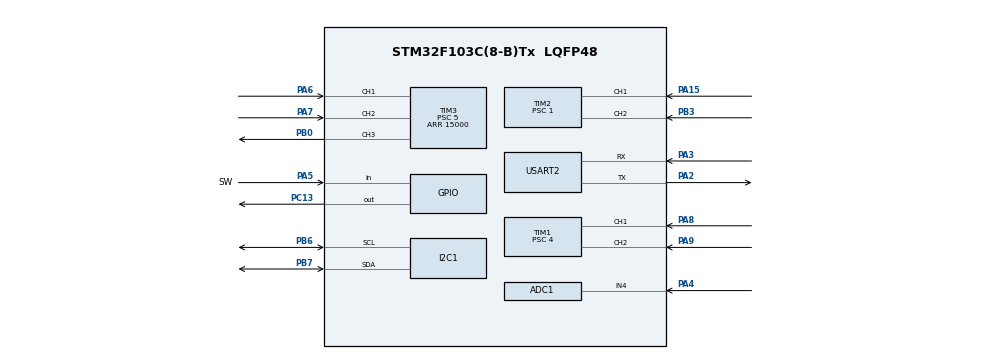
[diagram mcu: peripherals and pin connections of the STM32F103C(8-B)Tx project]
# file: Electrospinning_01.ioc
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ADC1.Channel-5\#ChannelRegularConversion=ADC_CHANNEL_4
ADC1.NbrOfConversionFlag=1
ADC1.Rank-5\#ChannelRegularConversion=1
ADC1.SamplingTime-5\#ChannelRegularConversion=ADC_SAMPLETIME_1CYCLE_5
ADC1.master=1
Mcu.Family=STM32F1
Mcu.Name=STM32F103C(8-B)Tx
Mcu.Package=LQFP48
NVIC.PriorityGroup=NVIC_PRIORITYGROUP_4
NVIC.TIM2_IRQn=true\:0\:0\:false\:false\:true\:true
NVIC.TIM4_IRQn=true\:0\:0\:false\:false\:true\:true
PA13.Mode=Serial_Wire
PA13.Signal=SYS_JTMS-SWDIO
PA14.Mode=Serial_Wire
PA14.Signal=SYS_JTCK-SWCLK
PA15.GPIO_PuPd=GPIO_PULLUP
PA15.Signal=S_TIM2_CH1_ETR
PA2.Mode=Asynchronous
PA2.Signal=USART2_TX
PA3.Mode=Asynchronous
PA3.Signal=USART2_RX
PA4.Signal=ADCx_IN4
PA5.GPIO_Label=SW
PA5.Signal=GPIO_Input
PA6.Signal=S_TIM3_CH1
PA7.Signal=S_TIM3_CH2
PA8.Signal=S_TIM1_CH1
PA9.Signal=S_TIM1_CH2
PB0.Signal=S_TIM3_CH3
PB3.GPIO_PuPd=GPIO_PULLUP
PB3.Signal=S_TIM2_CH2
PB6.Mode=I2C
PB6.Signal=I2C1_SCL
PB7.Mode=I2C
PB7.Signal=I2C1_SDA
PC13-TAMPER-RTC.Signal=GPIO_Output
PC14-OSC32_IN.Mode=LSE-External-Oscillator
PC14-OSC32_IN.Signal=RCC_OSC32_IN
PC15-OSC32_OUT.Mode=LSE-External-Oscillator
PC15-OSC32_OUT.Signal=RCC_OSC32_OUT
PD0-OSC_IN.Mode=HSE-External-Oscillator
PD0-OSC_IN.Signal=RCC_OSC_IN
PD1-OSC_OUT.Mode=HSE-External-Oscillator
PD1-OSC_OUT.Signal=RCC_OSC_OUT
ProjectManager.HeapSize=0x200
ProjectManager.StackSize=0x400
ProjectManager.TargetToolchain=MDK-ARM V5
RCC.APB1Freq_Value=8000000
RCC.APB2Freq_Value=8000000
SH.ADCx_IN4.0=ADC1_IN4,IN4
SH.S_TIM1_CH1.0=TIM1_CH1,Encoder_Interface
SH.S_TIM1_CH2.0=TIM1_CH2,Encoder_Interface
SH.S_TIM2_CH1_ETR.0=TIM2_CH1,Encoder_Interface
SH.S_TIM2_CH2.0=TIM2_CH2,Encoder_Interface
SH.S_TIM3_CH1.0=TIM3_CH1,Encoder_Interface
SH.S_TIM3_CH2.0=TIM3_CH2,Encoder_Interface
SH.S_TIM3_CH3.0=TIM3_CH3,PWM Generation3 CH3
TIM1.Prescaler=4
TIM2.EncoderMode=TIM_ENCODERMODE_TI1
TIM2.IC1Polarity=TIM_ICPOLARITY_FALLING
TIM2.IC2Filter=15
TIM2.IC2Polarity=TIM_ICPOLARITY_FALLING
TIM2.Period=0xffff
TIM2.Prescaler=1
TIM3.Channel-PWM\ Generation3\ CH3=TIM_CHANNEL_3
TIM3.Period=15000
TIM3.Prescaler=5
TIM4.AutoReloadPreload=TIM_AUTORELOAD_PRELOAD_ENABLE
TIM4.Period=100
TIM4.Prescaler=7200
USART2.VirtualMode=VM_ASYNC
VP_TIM4_VS_ClockSourceINT.Mode=Internal
board=custom

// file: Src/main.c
/* USER CODE BEGIN Header */
/**
  ******************************************************************************
  * @file           : main.c
  * @brief          : Main program body
  ******************************************************************************
  ** This notice applies to any and all portions of this file
  * that are not between comment pairs USER CODE BEGIN and
  * USER CODE END. Other portions of this file, whether
  * inserted by the user or by software development tools
  * are owned by their respective copyright owners.
  *
  * COPYRIGHT(c) 2019 STMicroelectronics
  *
  * Redistribution and use in source and binary forms, with or without modification,
  * are permitted provided that the following conditions are met:
  *   1. Redistributions of source code must retain the above copyright notice,
  *      this list of conditions and the following disclaimer.
  *   2. Redistributions in binary form must reproduce the above copyright notice,
  *      this list of conditions and the following disclaimer in the documentation
  *      and/or other materials provided with the distribution.
  *   3. Neither the name of STMicroelectronics nor the names of its contributors
  *      may be used to endorse or promote products derived from this software
  *      without specific prior written permission.
  *
  * THIS SOFTWARE IS PROVIDED BY THE COPYRIGHT HOLDERS AND CONTRIBUTORS "AS IS"
  * AND ANY EXPRESS OR IMPLIED WARRANTIES, INCLUDING, BUT NOT LIMITED TO, THE
  * IMPLIED WARRANTIES OF MERCHANTABILITY AND FITNESS FOR A PARTICULAR PURPOSE ARE
  * DISCLAIMED. IN NO EVENT SHALL THE COPYRIGHT HOLDER OR CONTRIBUTORS BE LIABLE
  * FOR ANY DIRECT, INDIRECT, INCIDENTAL, SPECIAL, EXEMPLARY, OR CONSEQUENTIAL
  * DAMAGES (INCLUDING, BUT NOT LIMITED TO, PROCUREMENT OF SUBSTITUTE GOODS OR
  * SERVICES; LOSS OF USE, DATA, OR PROFITS; OR BUSINESS INTERRUPTION) HOWEVER
  * CAUSED AND ON ANY THEORY OF LIABILITY, WHETHER IN CONTRACT, STRICT LIABILITY,
  * OR TORT (INCLUDING NEGLIGENCE OR OTHERWISE) ARISING IN ANY WAY OUT OF THE USE
  * OF THIS SOFTWARE, EVEN IF ADVISED OF THE POSSIBILITY OF SUCH DAMAGE.
  *
  ******************************************************************************
  */
/* USER CODE END Header */

#include "main.h"
#include "stm32f1xx_hal_lcd_i2c.h"
#include "stm32f1xx_hal_delay.h"
#include "stdio.h"
#include "stm32f1xx_it.h"
	int varControl;
	int varEncoderInput;
	int varEncoderMotor;
	static int varSelect;
	static int varCount;
	int  adcResult;
	char buffer[40];
	char buffer1[40];
	int  i;
	void user_pwm_setvalue(uint16_t value);
  int  sampleCount;
  TIM_OC_InitTypeDef sConfigOC = {0};

ADC_HandleTypeDef hadc1;

I2C_HandleTypeDef hi2c1;

TIM_HandleTypeDef htim1;
TIM_HandleTypeDef htim2;
TIM_HandleTypeDef htim3;
TIM_HandleTypeDef htim4;

UART_HandleTypeDef huart2;

void SystemClock_Config(void);
static void MX_GPIO_Init(void);
static void MX_TIM2_Init(void);
static void MX_I2C1_Init(void);
static void MX_USART2_UART_Init(void);
static void MX_ADC1_Init(void);
static void MX_TIM4_Init(void);
static void MX_TIM1_Init(void);
static void MX_TIM3_Init(void);

int main(void)
{

  /* MCU Configuration--------------------------------------------------------*/

  /* Reset of all peripherals, Initializes the Flash interface and the Systick. */
  HAL_Init();

  /* Configure the system clock */
  SystemClock_Config();

  /* Initialize all configured peripherals */
  MX_GPIO_Init();
  MX_TIM2_Init();
  MX_I2C1_Init();
  MX_USART2_UART_Init();
  MX_ADC1_Init();
  MX_TIM4_Init();
  MX_TIM1_Init();
  MX_TIM3_Init();
	HAL_TIM_Encoder_Start(&htim4,TIM_CHANNEL_ALL);
	HAL_TIM_Encoder_Start(&htim2,TIM_CHANNEL_ALL);
	HAL_TIM_Encoder_Start(&htim3,TIM_CHANNEL_ALL);
	HAL_TIM_Encoder_Start(&htim1,TIM_CHANNEL_ALL);

  /* Infinite loop */
  /* USER CODE BEGIN WHILE */
	lcdStartDisplay();

  while (1)
  {
		sConfigOC.Pulse = varEncoderInput;
		varEncoderInput = TIM3 -> CNT;
		varEncoderMotor = TIM2 -> CNT;

    /* USER CODE END WHILE */

		lcd_goto_XY(1,0);
		lcd_send_string("Set Run");
    sprintf(buffer,"%d",varEncoderInput);
		lcd_goto_XY(1,10);
		lcd_send_string(buffer);

		lcd_goto_XY(2,0);
		lcd_send_string("Real Speed:");
		sprintf(buffer,"%d",varEncoderMotor);
		lcd_goto_XY(2,10);
		lcd_send_string(buffer1);

  }
}

void SystemClock_Config(void)
{
  RCC_OscInitTypeDef RCC_OscInitStruct = {0};
  RCC_ClkInitTypeDef RCC_ClkInitStruct = {0};
  RCC_PeriphCLKInitTypeDef PeriphClkInit = {0};

  /**Initializes the CPU, AHB and APB busses clocks
  */
  RCC_OscInitStruct.OscillatorType = RCC_OSCILLATORTYPE_HSI;
  RCC_OscInitStruct.HSIState = RCC_HSI_ON;
  RCC_OscInitStruct.HSICalibrationValue = RCC_HSICALIBRATION_DEFAULT;
  RCC_OscInitStruct.PLL.PLLState = RCC_PLL_NONE;
  if (HAL_RCC_OscConfig(&RCC_OscInitStruct) != HAL_OK)
  {
    Error_Handler();
  }
  /**Initializes the CPU, AHB and APB busses clocks
  */
  RCC_ClkInitStruct.ClockType = RCC_CLOCKTYPE_HCLK|RCC_CLOCKTYPE_SYSCLK
                              |RCC_CLOCKTYPE_PCLK1|RCC_CLOCKTYPE_PCLK2;
  RCC_ClkInitStruct.SYSCLKSource = RCC_SYSCLKSOURCE_HSI;
  RCC_ClkInitStruct.AHBCLKDivider = RCC_SYSCLK_DIV1;
  RCC_ClkInitStruct.APB1CLKDivider = RCC_HCLK_DIV1;
  RCC_ClkInitStruct.APB2CLKDivider = RCC_HCLK_DIV1;

  if (HAL_RCC_ClockConfig(&RCC_ClkInitStruct, FLASH_LATENCY_0) != HAL_OK)
  {
    Error_Handler();
  }
  PeriphClkInit.PeriphClockSelection = RCC_PERIPHCLK_ADC;
  PeriphClkInit.AdcClockSelection = RCC_ADCPCLK2_DIV2;
  if (HAL_RCCEx_PeriphCLKConfig(&PeriphClkInit) != HAL_OK)
  {
    Error_Handler();
  }
}

static void MX_ADC1_Init(void)
{

  ADC_ChannelConfTypeDef sConfig = {0};

  /**Common config
  */
  hadc1.Instance = ADC1;
  hadc1.Init.ScanConvMode = ADC_SCAN_DISABLE;
  hadc1.Init.ContinuousConvMode = DISABLE;
  hadc1.Init.DiscontinuousConvMode = DISABLE;
  hadc1.Init.ExternalTrigConv = ADC_SOFTWARE_START;
  hadc1.Init.DataAlign = ADC_DATAALIGN_RIGHT;
  hadc1.Init.NbrOfConversion = 1;
  if (HAL_ADC_Init(&hadc1) != HAL_OK)
  {
    Error_Handler();
  }
  /**Configure Regular Channel
  */
  sConfig.Channel = ADC_CHANNEL_4;
  sConfig.Rank = ADC_REGULAR_RANK_1;
  sConfig.SamplingTime = ADC_SAMPLETIME_1CYCLE_5;
  if (HAL_ADC_ConfigChannel(&hadc1, &sConfig) != HAL_OK)
  {
    Error_Handler();
  }

}

static void MX_I2C1_Init(void)
{

  hi2c1.Instance = I2C1;
  hi2c1.Init.ClockSpeed = 100000;
  hi2c1.Init.DutyCycle = I2C_DUTYCYCLE_2;
  hi2c1.Init.OwnAddress1 = 0;
  hi2c1.Init.AddressingMode = I2C_ADDRESSINGMODE_7BIT;
  hi2c1.Init.DualAddressMode = I2C_DUALADDRESS_DISABLE;
  hi2c1.Init.OwnAddress2 = 0;
  hi2c1.Init.GeneralCallMode = I2C_GENERALCALL_DISABLE;
  hi2c1.Init.NoStretchMode = I2C_NOSTRETCH_DISABLE;
  if (HAL_I2C_Init(&hi2c1) != HAL_OK)
  {
    Error_Handler();
  }

}

static void MX_TIM1_Init(void)
{

  TIM_Encoder_InitTypeDef sConfig = {0};
  TIM_MasterConfigTypeDef sMasterConfig = {0};

  htim1.Instance = TIM1;
  htim1.Init.Prescaler = 4;
  htim1.Init.CounterMode = TIM_COUNTERMODE_UP;
  htim1.Init.Period = 0;
  htim1.Init.ClockDivision = TIM_CLOCKDIVISION_DIV1;
  htim1.Init.RepetitionCounter = 0;
  htim1.Init.AutoReloadPreload = TIM_AUTORELOAD_PRELOAD_DISABLE;
  sConfig.EncoderMode = TIM_ENCODERMODE_TI1;
  sConfig.IC1Polarity = TIM_ICPOLARITY_RISING;
  sConfig.IC1Selection = TIM_ICSELECTION_DIRECTTI;
  sConfig.IC1Prescaler = TIM_ICPSC_DIV1;
  sConfig.IC1Filter = 0;
  sConfig.IC2Polarity = TIM_ICPOLARITY_RISING;
  sConfig.IC2Selection = TIM_ICSELECTION_DIRECTTI;
  sConfig.IC2Prescaler = TIM_ICPSC_DIV1;
  sConfig.IC2Filter = 0;
  if (HAL_TIM_Encoder_Init(&htim1, &sConfig) != HAL_OK)
  {
    Error_Handler();
  }
  sMasterConfig.MasterOutputTrigger = TIM_TRGO_RESET;
  sMasterConfig.MasterSlaveMode = TIM_MASTERSLAVEMODE_DISABLE;
  if (HAL_TIMEx_MasterConfigSynchronization(&htim1, &sMasterConfig) != HAL_OK)
  {
    Error_Handler();
  }

}

static void MX_TIM2_Init(void)
{

  TIM_Encoder_InitTypeDef sConfig = {0};
  TIM_MasterConfigTypeDef sMasterConfig = {0};

  htim2.Instance = TIM2;
  htim2.Init.Prescaler = 1;
  htim2.Init.CounterMode = TIM_COUNTERMODE_UP;
  htim2.Init.Period = 0xffff;
  htim2.Init.ClockDivision = TIM_CLOCKDIVISION_DIV1;
  htim2.Init.AutoReloadPreload = TIM_AUTORELOAD_PRELOAD_DISABLE;
  sConfig.EncoderMode = TIM_ENCODERMODE_TI1;
  sConfig.IC1Polarity = TIM_ICPOLARITY_FALLING;
  sConfig.IC1Selection = TIM_ICSELECTION_DIRECTTI;
  sConfig.IC1Prescaler = TIM_ICPSC_DIV1;
  sConfig.IC1Filter = 0;
  sConfig.IC2Polarity = TIM_ICPOLARITY_FALLING;
  sConfig.IC2Selection = TIM_ICSELECTION_DIRECTTI;
  sConfig.IC2Prescaler = TIM_ICPSC_DIV1;
  sConfig.IC2Filter = 15;
  if (HAL_TIM_Encoder_Init(&htim2, &sConfig) != HAL_OK)
  {
    Error_Handler();
  }
  sMasterConfig.MasterOutputTrigger = TIM_TRGO_RESET;
  sMasterConfig.MasterSlaveMode = TIM_MASTERSLAVEMODE_DISABLE;
  if (HAL_TIMEx_MasterConfigSynchronization(&htim2, &sMasterConfig) != HAL_OK)
  {
    Error_Handler();
  }

}

static void MX_TIM3_Init(void)
{

  TIM_Encoder_InitTypeDef sConfig = {0};
  TIM_MasterConfigTypeDef sMasterConfig = {0};
  TIM_OC_InitTypeDef sConfigOC = {0};

  htim3.Instance = TIM3;
  htim3.Init.Prescaler = 5;
  htim3.Init.CounterMode = TIM_COUNTERMODE_UP;
  htim3.Init.Period = 15000;
  htim3.Init.ClockDivision = TIM_CLOCKDIVISION_DIV1;
  htim3.Init.AutoReloadPreload = TIM_AUTORELOAD_PRELOAD_DISABLE;
  if (HAL_TIM_PWM_Init(&htim3) != HAL_OK)
  {
    Error_Handler();
  }
  sConfig.EncoderMode = TIM_ENCODERMODE_TI1;
  sConfig.IC1Polarity = TIM_ICPOLARITY_RISING;
  sConfig.IC1Selection = TIM_ICSELECTION_DIRECTTI;
  sConfig.IC1Prescaler = TIM_ICPSC_DIV1;
  sConfig.IC1Filter = 15;
  sConfig.IC2Polarity = TIM_ICPOLARITY_RISING;
  sConfig.IC2Selection = TIM_ICSELECTION_DIRECTTI;
  sConfig.IC2Prescaler = TIM_ICPSC_DIV1;
  sConfig.IC2Filter = 0;
  if (HAL_TIM_Encoder_Init(&htim3, &sConfig) != HAL_OK)
  {
    Error_Handler();
  }
  sMasterConfig.MasterOutputTrigger = TIM_TRGO_RESET;
  sMasterConfig.MasterSlaveMode = TIM_MASTERSLAVEMODE_DISABLE;
  if (HAL_TIMEx_MasterConfigSynchronization(&htim3, &sMasterConfig) != HAL_OK)
  {
    Error_Handler();
  }
  sConfigOC.OCMode = TIM_OCMODE_PWM1;
  sConfigOC.Pulse = 0;
  sConfigOC.OCPolarity = TIM_OCPOLARITY_HIGH;
  sConfigOC.OCFastMode = TIM_OCFAST_DISABLE;
  if (HAL_TIM_PWM_ConfigChannel(&htim3, &sConfigOC, TIM_CHANNEL_3) != HAL_OK)
  {
    Error_Handler();
  }
  HAL_TIM_MspPostInit(&htim3);

}

static void MX_TIM4_Init(void)
{

  TIM_ClockConfigTypeDef sClockSourceConfig = {0};
  TIM_MasterConfigTypeDef sMasterConfig = {0};

  htim4.Instance = TIM4;
  htim4.Init.Prescaler = 7200;
  htim4.Init.CounterMode = TIM_COUNTERMODE_UP;
  htim4.Init.Period = 100;
  htim4.Init.ClockDivision = TIM_CLOCKDIVISION_DIV1;
  htim4.Init.AutoReloadPreload = TIM_AUTORELOAD_PRELOAD_ENABLE;
  if (HAL_TIM_Base_Init(&htim4) != HAL_OK)
  {
    Error_Handler();
  }
  sClockSourceConfig.ClockSource = TIM_CLOCKSOURCE_INTERNAL;
  if (HAL_TIM_ConfigClockSource(&htim4, &sClockSourceConfig) != HAL_OK)
  {
    Error_Handler();
  }
  sMasterConfig.MasterOutputTrigger = TIM_TRGO_RESET;
  sMasterConfig.MasterSlaveMode = TIM_MASTERSLAVEMODE_DISABLE;
  if (HAL_TIMEx_MasterConfigSynchronization(&htim4, &sMasterConfig) != HAL_OK)
  {
    Error_Handler();
  }

}

static void MX_USART2_UART_Init(void)
{

  huart2.Instance = USART2;
  huart2.Init.BaudRate = 115200;
  huart2.Init.WordLength = UART_WORDLENGTH_8B;
  huart2.Init.StopBits = UART_STOPBITS_1;
  huart2.Init.Parity = UART_PARITY_NONE;
  huart2.Init.Mode = UART_MODE_TX_RX;
  huart2.Init.HwFlowCtl = UART_HWCONTROL_NONE;
  huart2.Init.OverSampling = UART_OVERSAMPLING_16;
  if (HAL_UART_Init(&huart2) != HAL_OK)
  {
    Error_Handler();
  }

}

static void MX_GPIO_Init(void)
{
  GPIO_InitTypeDef GPIO_InitStruct = {0};

  /* GPIO Ports Clock Enable */
  __HAL_RCC_GPIOC_CLK_ENABLE();
  __HAL_RCC_GPIOD_CLK_ENABLE();
  __HAL_RCC_GPIOA_CLK_ENABLE();
  __HAL_RCC_GPIOB_CLK_ENABLE();

  /*Configure GPIO pin Output Level */
  HAL_GPIO_WritePin(GPIOC, GPIO_PIN_13, GPIO_PIN_RESET);

  /*Configure GPIO pin : PC13 */
  GPIO_InitStruct.Pin = GPIO_PIN_13;
  GPIO_InitStruct.Mode = GPIO_MODE_OUTPUT_PP;
  GPIO_InitStruct.Pull = GPIO_NOPULL;
  GPIO_InitStruct.Speed = GPIO_SPEED_FREQ_LOW;
  HAL_GPIO_Init(GPIOC, &GPIO_InitStruct);

  /*Configure GPIO pin : SW_Pin */
  GPIO_InitStruct.Pin = SW_Pin;
  GPIO_InitStruct.Mode = GPIO_MODE_INPUT;
  GPIO_InitStruct.Pull = GPIO_NOPULL;
  HAL_GPIO_Init(SW_GPIO_Port, &GPIO_InitStruct);

}

/* USER CODE BEGIN 4 */
//void user_pwm_setvalue(uint16_t value)
//{
//    TIM_OC_InitTypeDef sConfigOC;
//
//    sConfigOC.OCMode = TIM_OCMODE_PWM1;
//    sConfigOC.Pulse = value;
//    sConfigOC.OCPolarity = TIM_OCPOLARITY_HIGH;
//    sConfigOC.OCFastMode = TIM_OCFAST_DISABLE;
//    HAL_TIM_PWM_ConfigChannel(&htim3, &sConfigOC, TIM_CHANNEL_3);
//    HAL_TIM_PWM_Start(&htim3, TIM_CHANNEL_3);
//}
//void motorRun (int timeInput)
//{
//	HAL_GPIO_TogglePin(PWM__GPIO_Port,PWM__Pin);
//	HAL_Delay(timeInput);
//
//
//}
/* USER CODE END 4 */

void Error_Handler(void)
{
}

/************************ (C) COPYRIGHT STMicroelectronics *****END OF FILE****/
